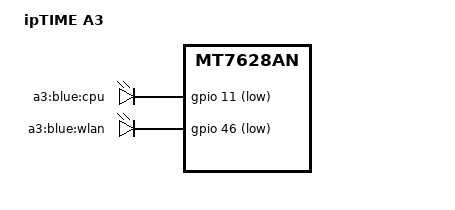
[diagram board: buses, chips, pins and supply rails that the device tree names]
// SPDX-License-Identifier: GPL-2.0-or-later OR MIT
/dts-v1/;

#include "mt7628an_iptime.dtsi"

/ {
	compatible = "iptime,a3", "mediatek,mt7628an-soc";
	model = "ipTIME A3";

	aliases {
		led-boot = &led_cpu;
		led-failsafe = &led_cpu;
		led-running = &led_cpu;
		led-upgrade = &led_cpu;
	};

	leds {
		compatible = "gpio-leds";

		led_cpu: cpu {
			label = "a3:blue:cpu";
			gpios = <&gpio 11 GPIO_ACTIVE_LOW>;
		};

		wlan {
			label = "a3:blue:wlan";
			gpios = <&gpio 46 GPIO_ACTIVE_LOW>;
			linux,default-trigger = "phy0tpt";
		};
	};
};

&esw {
	mediatek,portmap = <0x3e>;
	mediatek,portdisable = <0x32>;
};
